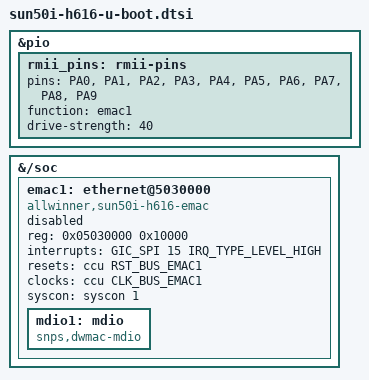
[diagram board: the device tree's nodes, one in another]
// SPDX-License-Identifier: GPL-2.0+
/*
 * Copyright (C) 2025 Jernej Skrabec <jernej.skrabec@gmail.com>
 */

&pio {
	/omit-if-no-ref/
	rmii_pins: rmii-pins {
		pins = "PA0", "PA1", "PA2", "PA3", "PA4",
			"PA5", "PA6", "PA7", "PA8", "PA9";
		function = "emac1";
		drive-strength = <40>;
	};
};

&{/soc} {
	emac1: ethernet@5030000 {
		compatible = "allwinner,sun50i-h616-emac";
		reg = <0x05030000 0x10000>;
		interrupts = <GIC_SPI 15 IRQ_TYPE_LEVEL_HIGH>;
		interrupt-names = "macirq";
		resets = <&ccu RST_BUS_EMAC1>;
		reset-names = "stmmaceth";
		clocks = <&ccu CLK_BUS_EMAC1>;
		clock-names = "stmmaceth";
		syscon = <&syscon 1>;
		status = "disabled";

		mdio1: mdio {
			compatible = "snps,dwmac-mdio";
			#address-cells = <1>;
			#size-cells = <0>;
		};
	};
};
